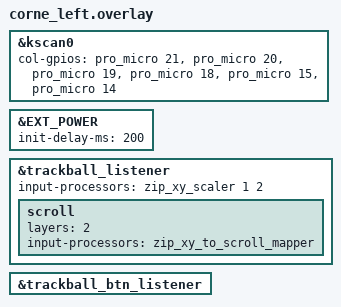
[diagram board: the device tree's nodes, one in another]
/*
 * Copyright (c) 2020 Pete Johanson
 *
 * SPDX-License-Identifier: MIT
 */

#include "corne.dtsi"
#include <input/processors.dtsi>

&kscan0 {
	col-gpios
		= <&pro_micro 21 GPIO_ACTIVE_HIGH>
		, <&pro_micro 20 GPIO_ACTIVE_HIGH>
		, <&pro_micro 19 GPIO_ACTIVE_HIGH>
		, <&pro_micro 18 GPIO_ACTIVE_HIGH>
		, <&pro_micro 15 GPIO_ACTIVE_HIGH>
		, <&pro_micro 14 GPIO_ACTIVE_HIGH>
		;
};

/* Give EXT_POWER time before OLED/RGB on VCC come up */
&EXT_POWER {
	init-delay-ms = <200>;
};

/* Central side: enable listeners for trackball events from the right half */
&trackball_listener {
	status = "okay";
	/* SCALE_DIVISOR = 2 from pinout */
	input-processors = <&zip_xy_scaler 1 2>;

	/* Layer 2 (raise): trackball scrolls */
	scroll {
		layers = <2>;
		input-processors = <&zip_xy_to_scroll_mapper>;
	};
};

&trackball_btn_listener {
	status = "okay";
};
